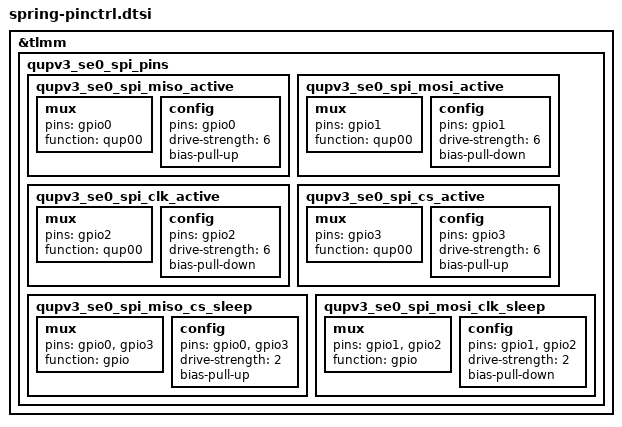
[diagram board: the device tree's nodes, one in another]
/* spring-pinctrl.dtsi */
&tlmm {
        qupv3_se0_spi_pins: qupv3_se0_spi_pins {
			qupv3_se0_spi_miso_active: qupv3_se0_spi_miso_active {
				mux {
					pins = "gpio0";
					function = "qup00";
				};

				config {
					pins = "gpio0";
					drive-strength = <6>;
					bias-pull-up;
				};
			};

			qupv3_se0_spi_mosi_active: qupv3_se0_spi_mosi_active {
				mux {
					pins = "gpio1";
					function = "qup00";
				};

				config {
					pins = "gpio1";
					drive-strength = <6>;
					bias-pull-down;
				};
			};

			qupv3_se0_spi_clk_active: qupv3_se0_spi_clk_active {
				mux {
					pins = "gpio2";
					function = "qup00";
				};

				config {
					pins = "gpio2";
					drive-strength = <6>;
					bias-pull-down;
				};
			};

			qupv3_se0_spi_cs_active: qupv3_se0_spi_cs_active {
				mux {
					pins = "gpio3";
					function = "qup00";
				};

				config {
					pins = "gpio3";
					drive-strength = <6>;
					bias-pull-up;
				};
			};
			qupv3_se0_spi_miso_cs_sleep: qupv3_se0_spi_miso_cs_sleep {
				mux {
					pins = "gpio0", "gpio3";
					function = "gpio";
				};

				config {
					pins = "gpio0", "gpio3";
					drive-strength = <2>;
					bias-pull-up;
				};
			};

			qupv3_se0_spi_mosi_clk_sleep: qupv3_se0_spi_mosi_clk_sleep {
				mux {
					pins = "gpio1", "gpio2";
					function = "gpio";
				};

				config {
					pins = "gpio1", "gpio2";
					drive-strength = <2>;
					bias-pull-down;
				};
			};
		};
};
